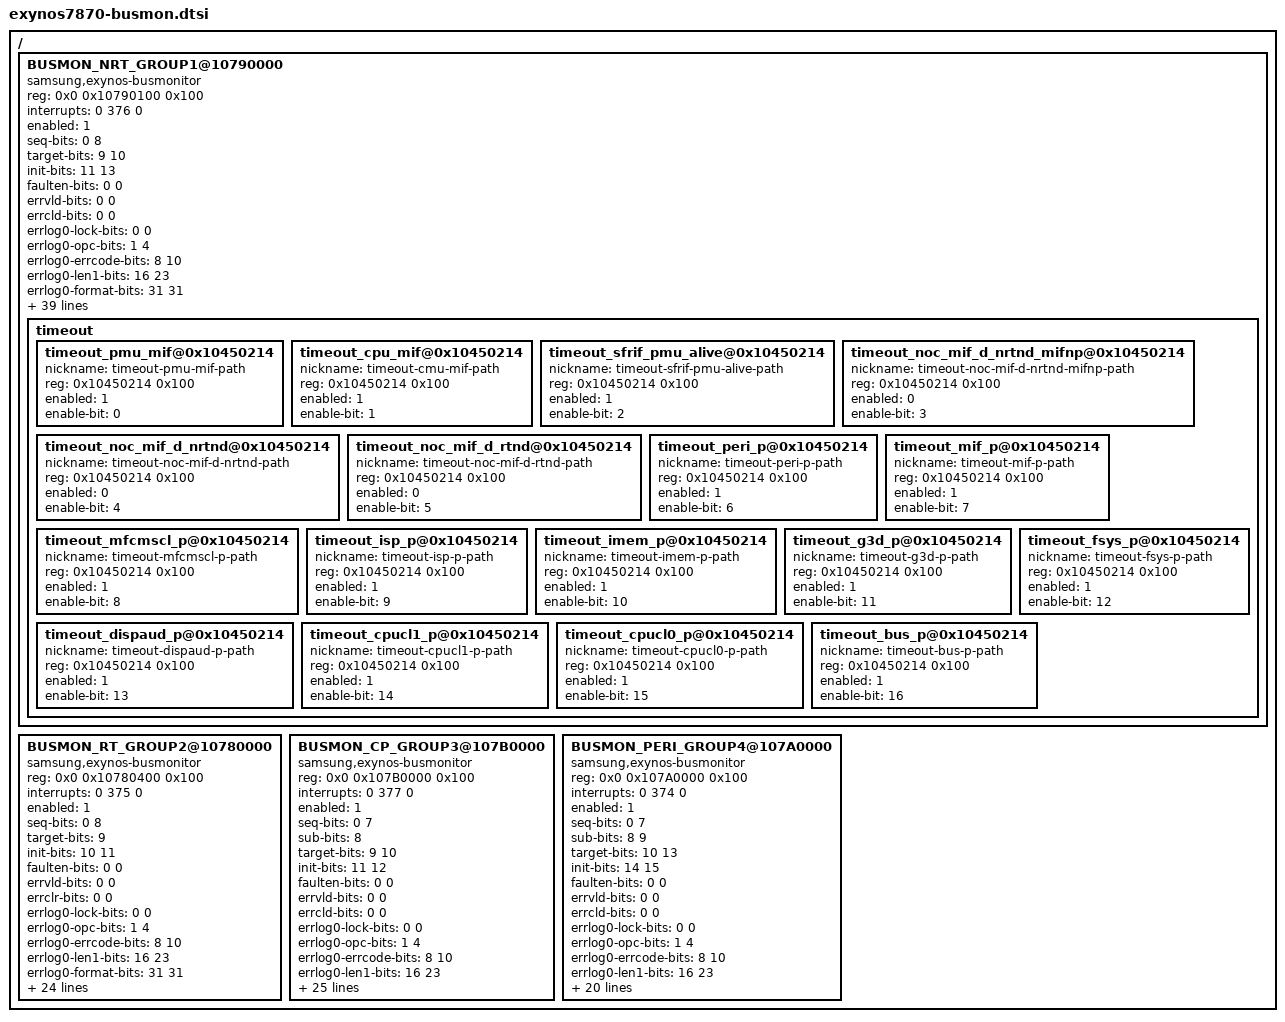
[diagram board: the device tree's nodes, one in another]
/*
 * SAMSUNG EXYNOS7870 SoC device tree source
 *
 * Copyright (c) 2015 Samsung Electronics Co., Ltd.
 *		http://www.samsung.com
 *
 * SAMSUNG EXYNOS7870 SoC device nodes are listed in this file.
 * EXYNOS7870 based board files can include this file and provide
 * values for board specfic bindings.
 *
 * This program is free software; you can redistribute it and/or modify
 * it under the terms of the GNU General Public License version 2 as
 * published by the Free Software Foundation.
 */

/ {
	BUSMON_NRT_GROUP1@10790000 {
		/* NRT - Group1 */
		compatible = "samsung,exynos-busmonitor";
		reg = <0x0 0x10790100 0x100>;
		interrupts  = <0 376 0>;
		#address-cells = <1>;
		#size-cells = <0>;
		enabled = <1>;

		/* Group-bit description */
		seq-bits = <0 8>;
		target-bits = <9 10>;
		init-bits = <11 13>;

		/* Group detail bit description */
		faulten-bits = <0 0>;
		errvld-bits = <0 0>;
		errcld-bits = <0 0>;
		errlog0-lock-bits = <0 0>;
		errlog0-opc-bits = <1 4>;
		errlog0-errcode-bits = <8 10>;
		errlog0-len1-bits = <16 23>;
		errlog0-format-bits = <31 31>;
		errlog1-bits = <0 13>;
		errlog2-bits = <0 0>;
		errlog3-bits = <0 31>;
		errlog4-bits = <0 3>;
		errlog5-bits = <0 14>;

		errlog5-axcache-bits = <0 3>;
		errlog5-axuser-bits = <4 7>;
		errlog5-axprot-bits = <8 10>;
		errlog5-axqos-bits = <11 14>;

		/* init, target, subrage detail description */
		init-num = <5>;
		target-num = <3>;
		sub-num = <1>;
		sub-array = <7>;

		init-desc =	"FSYS",
				"G3D",
				"ISPNRT",
				"MFCMSCL",
				"SRV_MIF_D_NRT";
		target-desc =	"DREX_NRT",
				"MIF_P",
				"SRV_MIF_D_NRT";

		sub-index = <0 1 3 4 6 9 14>;
		sub-addr = <0x0 0x0 0x0 0x0 0x0 0x0 0x10790000>;
		usersignal-desc =
				/* INIU_FSYS */
				"MMC55-64bits-0",	/* 0x00 */
				"MMC50-64bits-1",	/* 0x01 */
				"MMC50-64bits-2",	/* 0x02 */
				"SSS0",			/* 0x03 */
				"SSS1",			/* 0x04 */
				"RTIC",			/* 0x05 */
				"PDMA0",		/* 0x06 */
				"USB20DRD",		/* 0x07 */
				"MMC55-64bits-0",	/* 0x08 */
				"MMC50-64bits-1",	/* 0x09 */
				"MMC50-64bits-2",	/* 0x0A */
				"SSS0",			/* 0x0B */
				"SSS1",			/* 0x0C */
				"RTIC",			/* 0x0D */
				"PDMA1(Secure)", 	/* 0x0E */
				"USB20DRD",		/* 0x0F */
				"UNKNOWN",		/* 0x10 */
				"UNKNOWN",		/* 0x11 */
				"UNKNOWN",		/* 0x12 */
				"UNKNOWN",		/* 0x13 */
				"UNKNOWN",		/* 0x14 */
				"UNKNOWN",		/* 0x15 */
				"UNKNOWN",		/* 0x16 */
				"UNKNOWN",		/* 0x17 */
				"UNKNOWN",		/* 0x18 */
				"UNKNOWN",		/* 0x19 */
				"UNKNOWN",		/* 0x1A */
				"UNKNOWN",		/* 0x1B */
				"UNKNOWN",		/* 0x1C */
				"UNKNOWN",		/* 0x1D */
				"UNKNOWN",		/* 0x1E */
				"UNKNOWN",		/* 0x1F */

				/* INIU_ISPNRT */
				"CSIS0",		/* 0x20 */
				"FIMC-ISP",		/* 0x21 */
				"FIMC-VRA",		/* 0x22 */
				"UNKNOWN",		/* 0x23 */
				"CSIS1",		/* 0x24 */
				"MC_SCALER",		/* 0x25 */
				"FIMC-VRA",		/* 0x26 */
				"UNKNOWN",		/* 0x27 */
				"FIMC-BNS", 		/* 0x28 */
				"UNKNOWN",		/* 0x29 */
				"FIMC-VRA",		/* 0x2A */
				"UNKNOWN",		/* 0x2B */
				"UNKNOWN",		/* 0x2C */
				"UNKNOWN",		/* 0x2D */
				"FIMC-VRA",		/* 0x2E */
				"UNKNOWN",		/* 0x2F */
				"UNKNOWN",		/* 0x30 */
				"UNKNOWN",		/* 0x31 */
				"UNKNOWN",		/* 0x32 */
				"UNKNOWN",		/* 0x33 */
				"UNKNOWN",		/* 0x34 */
				"UNKNOWN",		/* 0x35 */
				"UNKNOWN",		/* 0x36 */
				"UNKNOWN",		/* 0x37 */
				"UNKNOWN",		/* 0x38 */
				"UNKNOWN",		/* 0x39 */
				"UNKNOWN",		/* 0x3A */
				"UNKNOWN",		/* 0x3B */
				"UNKNOWN",		/* 0x3C */
				"UNKNOWN",		/* 0x3D */
				"UNKNOWN",		/* 0x3E */
				"UNKNOWN",		/* 0x3F */

				/* INIU_MFCMSCL */
				"JPEG",			/* 0x40 */
				"MFC(1080p@60fps)",	/* 0x41 */
				"M2M Scaler Poly",	/* 0x42 */
				"MFC(1080p@60fps)",	/* 0x43 */
				"M2M Scaler BI",	/* 0x44 */
				"MFC(1080p@60fps)",	/* 0x45 */
				"UNKNOWN",		/* 0x46 */
				"MFC(1080p@60fps)",	/* 0x47 */
				"JPEG",			/* 0x48 */
				"MFC(1080p@60fps)",	/* 0x49 */
				"M2M Scaler Poly",	/* 0x4A */
				"MFC(1080p@60fps)",	/* 0x4B */
				"M2M Scaler BI",	/* 0x4C */
				"MFC(1080p@60fps)",	/* 0x4D */
				"UNKNOWN",		/* 0x4E */
				"MFC(1080p@60fps)";	/* 0x4F */

		timeout {
			#address-cells = <1>;
			#size-cells = <1>;
			timeout_pmu_mif@0x10450214 {
				nickname = "timeout-pmu-mif-path";
				reg = <0x10450214 0x100>;
				enabled = <1>;
				enable-bit = <0>;
			};
			timeout_cpu_mif@0x10450214 {
				nickname = "timeout-cmu-mif-path";
				reg = <0x10450214 0x100>;
				enabled = <1>;
				enable-bit = <1>;
			};
			timeout_sfrif_pmu_alive@0x10450214 {
				nickname = "timeout-sfrif-pmu-alive-path";
				reg = <0x10450214 0x100>;
				enabled = <1>;
				enable-bit = <2>;
			};
			timeout_noc_mif_d_nrtnd_mifnp@0x10450214 {
				nickname = "timeout-noc-mif-d-nrtnd-mifnp-path";
				reg = <0x10450214 0x100>;
				enabled = <0>;
				enable-bit = <3>;
			};
			timeout_noc_mif_d_nrtnd@0x10450214 {
				nickname = "timeout-noc-mif-d-nrtnd-path";
				reg = <0x10450214 0x100>;
				enabled = <0>;
				enable-bit = <4>;
			};
			timeout_noc_mif_d_rtnd@0x10450214 {
				nickname = "timeout-noc-mif-d-rtnd-path";
				reg = <0x10450214 0x100>;
				enabled = <0>;
				enable-bit = <5>;
			};
			timeout_peri_p@0x10450214 {
				nickname = "timeout-peri-p-path";
				reg = <0x10450214 0x100>;
				enabled = <1>;
				enable-bit = <6>;
			};
			timeout_mif_p@0x10450214 {
				nickname = "timeout-mif-p-path";
				reg = <0x10450214 0x100>;
				enabled = <1>;
				enable-bit = <7>;
			};
			timeout_mfcmscl_p@0x10450214 {
				nickname = "timeout-mfcmscl-p-path";
				reg = <0x10450214 0x100>;
				enabled = <1>;
				enable-bit = <8>;
			};
			timeout_isp_p@0x10450214 {
				nickname = "timeout-isp-p-path";
				reg = <0x10450214 0x100>;
				enabled = <1>;
				enable-bit = <9>;
			};
			timeout_imem_p@0x10450214 {
				nickname = "timeout-imem-p-path";
				reg = <0x10450214 0x100>;
				enabled = <1>;
				enable-bit = <10>;
			};
			timeout_g3d_p@0x10450214 {
				nickname = "timeout-g3d-p-path";
				reg = <0x10450214 0x100>;
				enabled = <1>;
				enable-bit = <11>;
			};
			timeout_fsys_p@0x10450214 {
				nickname = "timeout-fsys-p-path";
				reg = <0x10450214 0x100>;
				enabled = <1>;
				enable-bit = <12>;
			};
			timeout_dispaud_p@0x10450214 {
				nickname = "timeout-dispaud-p-path";
				reg = <0x10450214 0x100>;
				enabled = <1>;
				enable-bit = <13>;
			};
			timeout_cpucl1_p@0x10450214 {
				nickname = "timeout-cpucl1-p-path";
				reg = <0x10450214 0x100>;
				enabled = <1>;
				enable-bit = <14>;
			};
			timeout_cpucl0_p@0x10450214 {
				nickname = "timeout-cpucl0-p-path";
				reg = <0x10450214 0x100>;
				enabled = <1>;
				enable-bit = <15>;
			};
			timeout_bus_p@0x10450214 {
				nickname = "timeout-bus-p-path";
				reg = <0x10450214 0x100>;
				enabled = <1>;
				enable-bit = <16>;
			};
		};
	};

	BUSMON_RT_GROUP2@10780000 {
		/* RT */
		compatible = "samsung,exynos-busmonitor";
		reg = <0x0 0x10780400 0x100>;
		interrupts  = <0 375 0>;
		#address-cells = <1>;
		#size-cells = <0>;
		enabled = <1>;

		/* Group-bit description */
		seq-bits = <0 8>;
		target-bits = <9>;
		init-bits = <10 11>;

		/* Group detail bit rescription */
		faulten-bits = <0 0>;
		errvld-bits = <0 0>;
		errclr-bits = <0 0>;
		errlog0-lock-bits = <0 0>;
		errlog0-opc-bits = <1 4>;
		errlog0-errcode-bits = <8 10>;
		errlog0-len1-bits = <16 23>;
		errlog0-format-bits = <31 31>;
		errlog1-bits = <0 11>;
		errlog2-bits = <0 0>;
		errlog3-bits = <0 31>;
		errlog4-bits = <0 3>;
		errlog5-bits = <0 14>;

		errlog5-axcache-bits = <0 3>;
		errlog5-axuser-bits = <4 7>;
		errlog5-axprot-bits = <8 10>;
		errlog5-axqos-bits = <11 14>;

		/* init, target, subrage detail description */
		init-num = <3>;
		target-num = <2>;
		sub-num = <1>;
		sub-array = <3>;
		init-desc =	"DISPAUD",
				"ISP",
				"SRV_MIF_D_RT";
		target-desc =	"MIF_D_RT",
				"SRV_MIF_D_RT";

		sub-index = <0 2 5>;
		sub-addr = <0x0 0x0 0x10780000>;
		usersignal-desc =
			/* INIU_DISPAUD */
			"IDMA0",		/* 0x00 */
			"ADMA",			/* 0x01 */
			"IDMA1",		/* 0x02 */
			"ADMA",			/* 0x03 */
			"IDMA2",		/* 0x04 */
			"ADMA",			/* 0x05 */
			"UNKNOWN",		/* 0x06 */
			"ADMA",			/* 0x07 */
			"IDMA0",		/* 0x08 */
			"ADMA",			/* 0x09 */
			"IDMA1",		/* 0x0A */
			"ADMA",			/* 0x0B */
			"IDMA2",		/* 0x0C */
			"ADMA",			/* 0x0D */
			"UNKNOWN",		/* 0x0E */
			"ADMA",			/* 0x0F */

			/* INIU_ISP_RT */
			"CSIS0",		/* 0x10 */
			"FIMC-ISP",		/* 0x11 */
			"FIMC-VRA",		/* 0x12 */
			"UNKNOWN",		/* 0x13 */
			"CSIS1",		/* 0x14 */
			"MC_SCALER",		/* 0x15 */
			"FIMC-VRA",		/* 0x16 */
			"UNKNOWN",		/* 0x17 */
			"FIMC-BNS",		/* 0x18 */
			"UNKNOWN",		/* 0x19 */
			"FIMC-VRA",		/* 0x1A */
			"UNKNOWN",		/* 0x1B */
			"UNKNOWN",		/* 0x1C */
			"UNKNOWN",		/* 0x1D */
			"FIMC-VRA";		/* 0x1E */
	};

	BUSMON_CP_GROUP3@107B0000 {
		/* CP */
		compatible = "samsung,exynos-busmonitor";
		reg = <0x0 0x107B0000 0x100>;
		interrupts  = <0 377 0>;
		#address-cells = <1>;
		#size-cells = <0>;
		enabled = <1>;

		/* Group-bit description */
		seq-bits = <0 7>;
		sub-bits = <8>;
		target-bits = <9 10>;
		init-bits = <11 12>;

		/* Group detail bit rescription */
		faulten-bits = <0 0>;
		errvld-bits = <0 0>;
		errcld-bits = <0 0>;
		errlog0-lock-bits = <0 0>;
		errlog0-opc-bits = <1 4>;
		errlog0-errcode-bits = <8 10>;
		errlog0-len1-bits = <16 23>;
		errlog0-format-bits = <31 31>;
		errlog1-bits = <0 12>;
		errlog2-bits = <0 0>;
		errlog3-bits = <0 31>;
		errlog4-bits = <0 4>;
		errlog5-bits = <0 15>;

		errlog5-axcache-bits = <0 3>;
		errlog5-axuser-bits = <4 8>;
		errlog5-axprot-bits = <9 11>;
		errlog5-axqos-bits = <12 15>;

		/* init, target, subrage detail description */
		init-num = <3>;
		target-num = <3>;
		sub-num = <2>;
		sub-array = <9>;
		init-desc =	"GNSS",
				"MODEM",
				"SRV_MIF_D_CP";
		target-desc =	"MIF_D_CP",
				"MIF_D_CP_MIF_P",
				"SRV_MIF_D_CP";

		sub-index = <0 1 2 3 6 7 8 9 16>;
		sub-addr = <0x4000000 0x0 0x0 0x10000000 0x4000000
			0x0 0x0 0x10000000 0x107b0000>;
		usersignal-desc =
			/* INIU_MODEM */
			"CR7M",		/* 0x00 */
			"CR7M",		/* 0x01 */
			"CR7M",		/* 0x02 */
			"CR7M",		/* 0x03 */
			"CR7M",		/* 0x04 */
			"CR7M",		/* 0x05 */
			"CR7M",		/* 0x06 */
			"CR7M",		/* 0x07 */
			"TL3MtoL2",	/* 0x08 */
			"TL3MtoL2",	/* 0x09 */
			"TL3MtoL2",	/* 0x0A */
			"TL3MtoL2",	/* 0x0B */
			"TL3MtoL2",	/* 0x0C */
			"TL3MtoL2",	/* 0x0D */
			"TL3MtoL2",	/* 0x0E */
			"TL3MtoL2",	/* 0x0F */
			"DMA",		/* 0x10 */
			"DMA",		/* 0x11 */
			"DMA",		/* 0x12 */
			"DMA",		/* 0x13 */
			"CSXAP",	/* 0x14 */
			"DMtoL2",	/* 0x15 */
			"LMAC",		/* 0x16 */
			"HMtoL2";	/* 0x17 */
	};

	BUSMON_PERI_GROUP4@107A0000 {
		/* PERI */
		compatible = "samsung,exynos-busmonitor";
		reg = <0x0 0x107A0000 0x100>;
		interrupts  = <0 374 0>;
		#address-cells = <1>;
		#size-cells = <0>;
		enabled = <1>;

		/* Group-bit description */
		seq-bits = <0 7>;
		sub-bits = <8 9>;
		target-bits = <10 13>;
		init-bits = <14 15>;

		/* Group detail bit rescription */
		faulten-bits = <0 0>;
		errvld-bits = <0 0>;
		errcld-bits = <0 0>;
		errlog0-lock-bits = <0 0>;
		errlog0-opc-bits = <1 4>;
		errlog0-errcode-bits = <8 10>;
		errlog0-len1-bits = <16 23>;
		errlog0-format-bits = <31 31>;
		errlog1-bits = <0 15>;
		errlog2-bits = <0 0>;
		errlog3-bits = <0 0>;
		errlog4-bits = <0 0>;
		errlog5-bits = <0 10>;

		errlog5-axcache-bits = <0 3>;
		errlog5-axprot-bits = <5 7>;

		/* init, target, subrage detail description */
		init-num = <3>;
		target-num = <13>;
		sub-num = <4>;
		sub-array = <42>;
		init-desc =	"CP",
				"CPU",
				"NRT";
		target-desc =	"CPUCL1",
				"BUS",
				"CPUCL0",
				"DISPAUD",
				"FSYS",
				"G3D",
				"GIC",
				"ISP",
				"INTMEM",
				"MFCMSCL",
				"MIF",
				"PERI",
				"SRV_MIF";

		sub-index = <0 4 8 12 13 16 17 18 20 24
			28 28 29 36 40 41 44 45 48 52
			56 60 64 65 68 69 70 72 76 80
			80 81 88 92 93 96 97 100 152 153
			148 149>;
		sub-addr = <0x10800000 0x10780000 0x10900000 0x14800000 0x3000000
			0x13400000 0x0 0x4000000 0x11400000 0x104e0000
			0x14400000 0x2000000 0x0 0x12c00000 0x10400000
			0x16000000 0x10000000 0x13800000 0x107a0000 0x10800000
			0x10780000 0x10900000 0x14800000 0x3000000 0x13400000
			0x0 0x4000000 0x11400000 0x104e0000 0x14400000
			0x2000000 0x0 0x12c00000 0x10400000 0x16000000
			0x10000000 0x13800000 0x107a0000 0x2000000 0x0
			0x10000000 0x13800000>;
	};
};
